# CM_DPLL register map
Vendor: Texas Instruments
Peripheral module from a debugger description file (folder am335x).
Registers are 32-bit, access per field, no defined reset value unless marked. A register's access mark holds for its fields unless they carry their own. Offsets are as the file gives them; lines under a group give offsets from that group; [hi:lo] are bit positions; {n}, {i} and the like mark numbered series; 'fields as' and 'values as' point back to an identical list; <NAME> marks a mode.

## CM_DPLL
0x04 CLKSEL_TIMER7_CLK — Selects the Mux select line for TIMER7 clock [warm reset insensitive]
  [1:0] CLKSEL rw
    0=SEL1 (Select TCLKIN clock); 1=SEL2 (Select CLK_M_OSC clock); 2=SEL3 (Select CLK_32KHZ clock); 3=SEL4 (Reserved)
{0x0+4i} CLKSEL_TIMER{i}_CLK (i=2..4) — Selects the Mux select line for TIMER{i} clock [warm reset insensitive]
  fields as CLKSEL_TIMER7_CLK
0x14 CM_MAC_CLKSEL — Selects the clock divide ration for MII clock [warm reset insensitive]
  [2] MII_CLK_SEL rw — MII Clock Divider Selection. This bit is warm reset insensitive when CPSW RESET_ISO is enabled
    0=SEL0 (Selects 1/2 divider of SYSCLK2); 1=SEL1 (Selects 1/5 divide ratio of SYSCLK2)
0x18 CLKSEL_TIMER5_CLK — Selects the Mux select line for TIMER5 clock [warm reset insensitive]
  fields as CLKSEL_TIMER7_CLK
0x1C CLKSEL_TIMER6_CLK — Selects the Mux select line for TIMER6 clock [warm reset insensitive]
  fields as CLKSEL_TIMER7_CLK
0x20 CM_CPTS_RFT_CLKSEL — Selects the Mux select line for CPTS RFT clock [warm reset insensitive]
  [0] CLKSEL rw — Selects the Mux select line for cpgmac rft clock [warm reset insensitive]
    0=SEL1 (Selects CORE_CLKOUTM5); 1=SEL2 (Selects CORE_CLKOUTM4)
0x28 CLKSEL_TIMER1MS_CLK — Selects the Mux select line for TIMER1 clock [warm reset insensitive]
  [2:0] CLKSEL rw — Selects the Mux select line for DMTIMER_1MS clock [warm reset insensitive]
    0=SEL1 (Select CLK_M_OSC clock); 1=SEL2 (Select CLK_32KHZ clock); 2=SEL3 (Select TCLKIN clock); 3=SEL4 (Select CLK_RC32K clock); 4=SEL5 (Selects the CLK_32768 from 32KHz Crystal Osc)
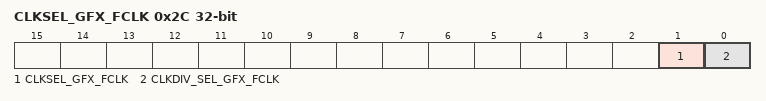
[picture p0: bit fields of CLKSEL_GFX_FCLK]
0x2C CLKSEL_GFX_FCLK — Selects the divider value for GFX clock [warm reset insensitive]
  [1] CLKSEL_GFX_FCLK rw — Selects the clock on gfx fclk [warm reset insensitive]
    0=SEL0 (SGX FCLK is from CORE PLL (same as L3 clock)); 1=SEL1 (SGX FCLK is from PER PLL (192 MHz clock))
  [0] CLKDIV_SEL_GFX_FCLK rw — Selects the divider value on gfx fclk [warm reset insensitive]
    0=DIV1 (SGX FCLK is same as L3 Clock or 192MHz Clock); 1=DIV2 (SGX FCLK is L3 clock/2 or 192Mhz/2)
0x30 CLKSEL_PRU_ICSS_OCP_CLK — Controls the Mux select line for PRU-ICSS OCP clock [warm reset insensitive]
  [0] CLKSEL rw — Controls Mux Select of PRU-ICSS OCP clock mux
    0=SEL1 (Select L3F clock as OCP Clock of PRU-ICSS); 1=SEL2 (Select DISP DPLL clock as OCP clock of PRU-ICSS)
0x34 CLKSEL_LCDC_PIXEL_CLK — Controls the Mux select line for LCDC PIXEL clock [warm reset insensitive]
  [1:0] CLKSEL rw — Controls the Mux Select of LCDC PIXEL clock
    0=SEL1 (Select DISP PLL CLKOUTM2); 1=SEL2 (Select CORE PLL CLKOUTM5); 2=SEL3 (Select PER PLL CLKOUTM2); 3=SEL4 (Reserved)
0x38 CLKSEL_WDT1_CLK — Selects the Mux select line for Watchdog1 clock [warm reset insensitive]
  [0] CLKSEL rw — Selects the Mux select line for WDT1 clock [warm reset insensitive]
    0=SEL1 (Select 32KHZ clock from RC Oscillator); 1=SEL2 (Select 32KHZ from 32K Clock divider)
0x3C CLKSEL_GPIO0_DBCLK — Selects the Mux select line for GPIO0 debounce clock [warm reset insensitive]
  [1:0] CLKSEL rw
    0=SEL1 (Select 32KHZ clock from RC Oscillator); 1=SEL2 (Select 32KHZ from 32K Crystal Oscillator); 2=SEL3 (Select 32KHz from Clock Divider)
